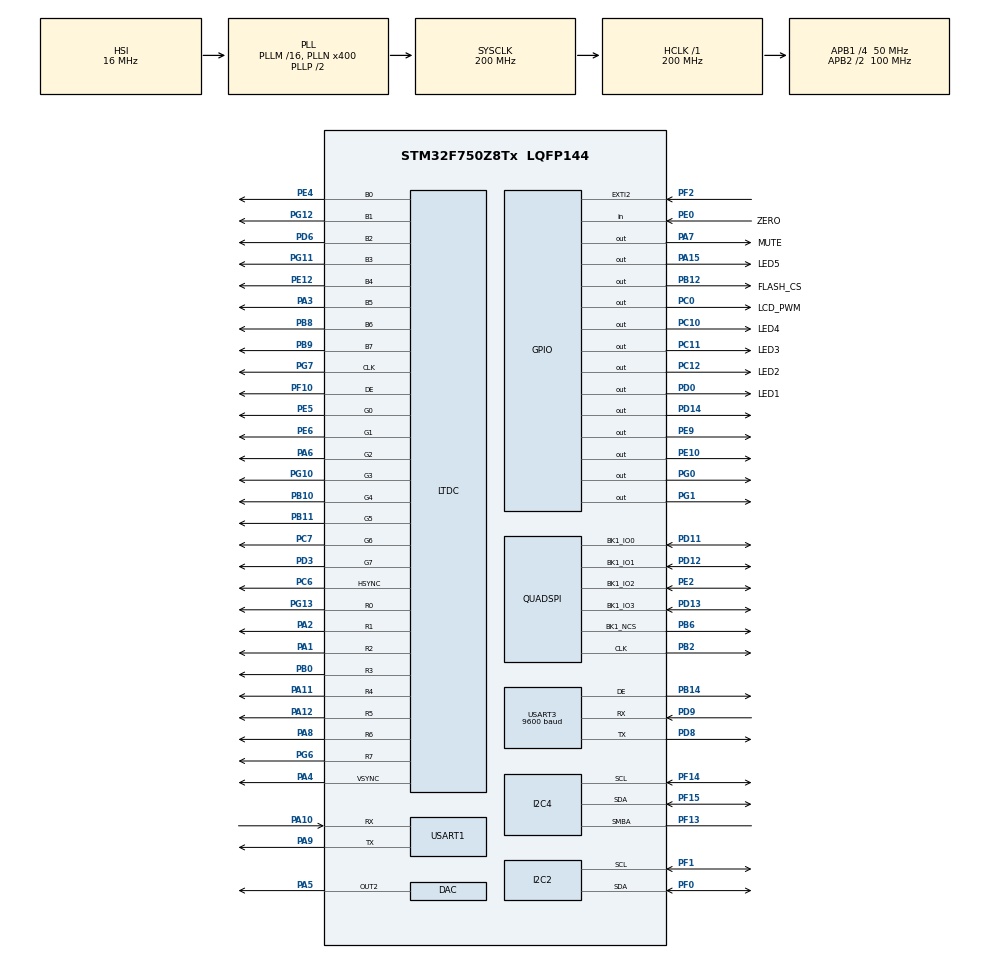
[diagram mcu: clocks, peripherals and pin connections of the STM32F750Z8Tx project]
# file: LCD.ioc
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CORTEX_M7.ART_ACCLERATOR_ENABLE=0
CORTEX_M7.CPU_DCache=Disabled
CORTEX_M7.CPU_ICache=Disabled
CORTEX_M7.PREFETCH_ENABLE=0
DAC.DAC_Trigger2=DAC_TRIGGER_NONE
DMA2D.ColorMode=DMA2D_OUTPUT_RGB565
Dma.I2C2_RX.1.Direction=DMA_PERIPH_TO_MEMORY
Dma.I2C2_RX.1.FIFOMode=DMA_FIFOMODE_DISABLE
Dma.I2C2_RX.1.Instance=DMA1_Stream2
Dma.I2C2_RX.1.MemDataAlignment=DMA_MDATAALIGN_BYTE
Dma.I2C2_RX.1.MemInc=DMA_MINC_ENABLE
Dma.I2C2_RX.1.Mode=DMA_CIRCULAR
Dma.I2C2_RX.1.PeriphDataAlignment=DMA_PDATAALIGN_BYTE
Dma.I2C2_RX.1.PeriphInc=DMA_PINC_DISABLE
Dma.I2C2_RX.1.Priority=DMA_PRIORITY_LOW
Dma.QUADSPI.2.Direction=DMA_PERIPH_TO_MEMORY
Dma.QUADSPI.2.FIFOMode=DMA_FIFOMODE_DISABLE
Dma.QUADSPI.2.Instance=DMA2_Stream7
Dma.QUADSPI.2.MemDataAlignment=DMA_MDATAALIGN_BYTE
Dma.QUADSPI.2.MemInc=DMA_MINC_ENABLE
Dma.QUADSPI.2.Mode=DMA_NORMAL
Dma.QUADSPI.2.PeriphDataAlignment=DMA_PDATAALIGN_BYTE
Dma.QUADSPI.2.PeriphInc=DMA_PINC_DISABLE
Dma.QUADSPI.2.Priority=DMA_PRIORITY_LOW
Dma.Request0=USART1_RX
Dma.Request1=I2C2_RX
Dma.Request2=QUADSPI
Dma.USART1_RX.0.Direction=DMA_PERIPH_TO_MEMORY
Dma.USART1_RX.0.FIFOMode=DMA_FIFOMODE_DISABLE
Dma.USART1_RX.0.Instance=DMA2_Stream2
Dma.USART1_RX.0.MemDataAlignment=DMA_MDATAALIGN_BYTE
Dma.USART1_RX.0.MemInc=DMA_MINC_ENABLE
Dma.USART1_RX.0.Mode=DMA_CIRCULAR
Dma.USART1_RX.0.PeriphDataAlignment=DMA_PDATAALIGN_BYTE
Dma.USART1_RX.0.PeriphInc=DMA_PINC_DISABLE
Dma.USART1_RX.0.Priority=DMA_PRIORITY_LOW
I2C2.Speed=10
I2C2.Timing=0xC00083FB
I2C4.Timeout=0x00008262
I2C4.Timing=0x00C0EAFF
IWDG.Prescaler=IWDG_PRESCALER_16
LTDC.ActiveH=272
LTDC.ActiveW=480
LTDC.Alpha_L0=255
LTDC.Alpha_L1=255
LTDC.BlendingFactor1_L0=LTDC_BLENDING_FACTOR1_CA
LTDC.BlendingFactor1_L1=LTDC_BLENDING_FACTOR1_PAxCA
LTDC.BlendingFactor2_L0=LTDC_BLENDING_FACTOR2_CA
LTDC.BlendingFactor2_L1=LTDC_BLENDING_FACTOR2_PAxCA
LTDC.Blue=255
LTDC.Blue_L0=0
LTDC.Blue_L1=255
LTDC.Green=255
LTDC.Green_L0=0
LTDC.Green_L1=255
LTDC.HBP=43
LTDC.HFP=8
LTDC.HSync=4
LTDC.ImageHeight_L0=272
LTDC.ImageWidth_L0=480
LTDC.Layers=0
LTDC.PixelFormat_L0=LTDC_PIXEL_FORMAT_RGB565
LTDC.PixelFormat_L1=LTDC_PIXEL_FORMAT_RGB565
LTDC.Red=255
LTDC.Red_L0=0
LTDC.VBP=12
LTDC.VFP=8
LTDC.VSync=4
LTDC.WindowX0_L1=160
LTDC.WindowX1_L0=480
LTDC.WindowX1_L1=480
LTDC.WindowY0_L1=32
LTDC.WindowY1_L0=272
LTDC.WindowY1_L1=272
Mcu.Family=STM32F7
Mcu.Name=STM32F750Z8Tx
Mcu.Package=LQFP144
Mcu.UserConstants=RK043FN48H_HSYNC,41;RK043FN48H_HBP,13;RK043FN48H_HFP,32;RK043FN48H_VSYNC,10;RK043FN48H_VBP,2;RK043FN48H_VFP,2
NVIC.DMA1_Stream2_IRQn=true\:0\:0\:false\:false\:true\:false\:true
NVIC.DMA2_Stream2_IRQn=true\:0\:0\:false\:false\:true\:false\:true
NVIC.DMA2_Stream7_IRQn=true\:0\:0\:false\:false\:true\:false\:true
NVIC.PVD_IRQn=true\:0\:0\:false\:false\:true\:true\:true
NVIC.PriorityGroup=NVIC_PRIORITYGROUP_4
NVIC.QUADSPI_IRQn=true\:0\:0\:false\:false\:true\:true\:true
NVIC.TIM1_UP_TIM10_IRQn=true\:0\:0\:false\:false\:true\:false\:true
NVIC.TIM6_DAC_IRQn=true\:0\:0\:false\:false\:true\:true\:true
NVIC.TIM7_IRQn=true\:0\:0\:false\:false\:true\:true\:true
NVIC.TimeBase=TIM1_UP_TIM10_IRQn
NVIC.TimeBaseIP=TIM1
NVIC.USART3_IRQn=true\:0\:0\:false\:false\:true\:true\:true
PA1.Mode=RGB888
PA1.Signal=LTDC_R2
PA10.Mode=Asynchronous
PA10.Signal=USART1_RX
PA11.Mode=RGB888
PA11.Signal=LTDC_R4
PA12.Mode=RGB888
PA12.Signal=LTDC_R5
PA13.Mode=Serial_Wire
PA13.Signal=SYS_JTMS-SWDIO
PA14.Mode=Serial_Wire
PA14.Signal=SYS_JTCK-SWCLK
PA15.GPIO_Label=LED5
PA15.GPIO_ModeDefaultOutputPP=GPIO_MODE_OUTPUT_PP
PA15.GPIO_PuPd=GPIO_NOPULL
PA15.GPIO_Speed=GPIO_SPEED_FREQ_LOW
PA15.PinState=GPIO_PIN_RESET
PA15.Signal=GPIO_Output
PA2.Mode=RGB888
PA2.Signal=LTDC_R1
PA3.Mode=RGB888
PA3.Signal=LTDC_B5
PA4.Mode=RGB888
PA4.Signal=LTDC_VSYNC
PA5.Signal=COMP_DAC2_group
PA6.Mode=RGB888
PA6.Signal=LTDC_G2
PA7.GPIO_Label=MUTE
PA7.GPIO_ModeDefaultOutputPP=GPIO_MODE_OUTPUT_PP
PA7.GPIO_PuPd=GPIO_NOPULL
PA7.GPIO_Speed=GPIO_SPEED_FREQ_LOW
PA7.PinState=GPIO_PIN_RESET
PA7.Signal=GPIO_Output
PA8.Mode=RGB888
PA8.Signal=LTDC_R6
PA9.Mode=Asynchronous
PA9.Signal=USART1_TX
PB0.Mode=RGB888
PB0.Signal=LTDC_R3
PB10.Mode=RGB888
PB10.Signal=LTDC_G4
PB11.Mode=RGB888
PB11.Signal=LTDC_G5
PB12.GPIO_Label=FLASH_CS
PB12.Signal=GPIO_Output
PB14.Mode=Hardware Flow Control (RS485)
PB14.Signal=USART3_DE
PB2.Mode=Single Bank 1
PB2.Signal=QUADSPI_CLK
PB6.Mode=Single Bank 1
PB6.Signal=QUADSPI_BK1_NCS
PB8.Mode=RGB888
PB8.Signal=LTDC_B6
PB9.Mode=RGB888
PB9.Signal=LTDC_B7
PC0.GPIO_Label=LCD_PWM
PC0.GPIO_ModeDefaultOutputPP=GPIO_MODE_OUTPUT_PP
PC0.GPIO_PuPd=GPIO_NOPULL
PC0.GPIO_Speed=GPIO_SPEED_FREQ_LOW
PC0.PinState=GPIO_PIN_RESET
PC0.Signal=GPIO_Output
PC10.GPIO_Label=LED4
PC10.GPIO_ModeDefaultOutputPP=GPIO_MODE_OUTPUT_PP
PC10.GPIO_PuPd=GPIO_NOPULL
PC10.GPIO_Speed=GPIO_SPEED_FREQ_LOW
PC10.PinState=GPIO_PIN_RESET
PC10.Signal=GPIO_Output
PC11.GPIO_Label=LED3
PC11.GPIO_ModeDefaultOutputPP=GPIO_MODE_OUTPUT_PP
PC11.GPIO_PuPd=GPIO_NOPULL
PC11.GPIO_Speed=GPIO_SPEED_FREQ_LOW
PC11.PinState=GPIO_PIN_RESET
PC11.Signal=GPIO_Output
PC12.GPIO_Label=LED2
PC12.GPIO_ModeDefaultOutputPP=GPIO_MODE_OUTPUT_PP
PC12.GPIO_PuPd=GPIO_NOPULL
PC12.GPIO_Speed=GPIO_SPEED_FREQ_LOW
PC12.PinState=GPIO_PIN_RESET
PC12.Signal=GPIO_Output
PC14/OSC32_IN.Mode=LSE-External-Oscillator
PC14/OSC32_IN.Signal=RCC_OSC32_IN
PC15/OSC32_OUT.Mode=LSE-External-Oscillator
PC15/OSC32_OUT.Signal=RCC_OSC32_OUT
PC6.Mode=RGB888
PC6.Signal=LTDC_HSYNC
PC7.Mode=RGB888
PC7.Signal=LTDC_G6
PD0.GPIO_Label=LED1
PD0.GPIO_ModeDefaultOutputPP=GPIO_MODE_OUTPUT_PP
PD0.GPIO_PuPd=GPIO_NOPULL
PD0.GPIO_Speed=GPIO_SPEED_FREQ_LOW
PD0.PinState=GPIO_PIN_RESET
PD0.Signal=GPIO_Output
PD11.Mode=Single Bank 1
PD11.Signal=QUADSPI_BK1_IO0
PD12.Mode=Single Bank 1
PD12.Signal=QUADSPI_BK1_IO1
PD13.Mode=Single Bank 1
PD13.Signal=QUADSPI_BK1_IO3
PD14.Signal=GPIO_Output
PD3.Mode=RGB888
PD3.Signal=LTDC_G7
PD6.Mode=RGB888
PD6.Signal=LTDC_B2
PD8.Mode=Asynchronous
PD8.Signal=USART3_TX
PD9.Mode=Asynchronous
PD9.Signal=USART3_RX
PE0.GPIO_Label=ZERO
PE0.Signal=GPIO_Input
PE10.Signal=GPIO_Output
PE12.Mode=RGB888
PE12.Signal=LTDC_B4
PE2.Mode=Single Bank 1
PE2.Signal=QUADSPI_BK1_IO2
PE4.Mode=RGB888
PE4.Signal=LTDC_B0
PE5.Mode=RGB888
PE5.Signal=LTDC_G0
PE6.Mode=RGB888
PE6.Signal=LTDC_G1
PE9.Signal=GPIO_Output
PF0.Mode=I2C
PF0.Signal=I2C2_SDA
PF1.Mode=I2C
PF1.Signal=I2C2_SCL
PF10.Mode=RGB888
PF10.Signal=LTDC_DE
PF13.Mode=SMBus-Alert-mode
PF13.Signal=I2C4_SMBA
PF14.Mode=SMBus-Alert-mode
PF14.Signal=I2C4_SCL
PF15.Mode=SMBus-Alert-mode
PF15.Signal=I2C4_SDA
PF2.GPIO_ModeDefaultEXTI=GPIO_MODE_IT_RISING
PF2.GPIO_PuPd=GPIO_NOPULL
PF2.Signal=GPXTI2
PG0.Signal=GPIO_Output
PG1.Signal=GPIO_Output
PG10.Mode=RGB888
PG10.Signal=LTDC_G3
PG11.Mode=RGB888
PG11.Signal=LTDC_B3
PG12.Mode=RGB888
PG12.Signal=LTDC_B1
PG13.Mode=RGB888
PG13.Signal=LTDC_R0
PG6.Mode=RGB888
PG6.Signal=LTDC_R7
PG7.Mode=RGB888
PG7.Signal=LTDC_CLK
PH0/OSC_IN.Mode=HSE-External-Oscillator
PH0/OSC_IN.Signal=RCC_OSC_IN
PH1/OSC_OUT.Mode=HSE-External-Oscillator
PH1/OSC_OUT.Signal=RCC_OSC_OUT
ProjectManager.HeapSize=0x200
ProjectManager.StackSize=0x400
ProjectManager.TargetToolchain=MDK-ARM V5
QUADSPI.ChipSelectHighTime=QSPI_CS_HIGH_TIME_3_CYCLE
QUADSPI.ClockPrescaler=10
QUADSPI.FifoThreshold=4
QUADSPI.FlashSize=24
QUADSPI.SampleShifting=QSPI_SAMPLE_SHIFTING_NONE
RCC.AHBFreq_Value=200000000
RCC.APB1CLKDivider=RCC_HCLK_DIV4
RCC.APB1Freq_Value=50000000
RCC.APB1TimFreq_Value=100000000
RCC.APB2CLKDivider=RCC_HCLK_DIV2
RCC.APB2Freq_Value=100000000
RCC.APB2TimFreq_Value=200000000
RCC.CortexFreq_Value=200000000
RCC.HCLKFreq_Value=200000000
RCC.HSE_VALUE=8000000
RCC.HSI_VALUE=16000000
RCC.PLLN=400
RCC.PLLSAIR=5
RCC.PLLSAIRDiv=RCC_PLLSAIDIVR_4
RCC.RTCClockSelection=RCC_RTCCLKSOURCE_LSE
RCC.SYSCLKFreq_VALUE=200000000
RCC.SYSCLKSource=RCC_SYSCLKSOURCE_PLLCLK
RCC.USBFreq_Value=200000000
RCC.VCOOutputFreq_Value=400000000
RTC.Alarm-Alarm\ A=RTC_ALARM_A
RTC.AsynchPrediv=128-1
RTC.SynchPrediv=256-1
SH.COMP_DAC2_group.0=DAC_OUT2,DAC_OUT2
STMicroelectronics.X-CUBE-TOUCHGFX.4.13.0.ApplicationCcGraphicsJjApplication=TouchGFXOoGenerator
STMicroelectronics.X-CUBE-TOUCHGFX.4.13.0.tgfx_display_interface=disp_ltdc
STMicroelectronics.X-CUBE-TOUCHGFX.4.13.0.tgfx_hardware_accelerator=dma_none
STMicroelectronics.X-CUBE-TOUCHGFX.4.13.0.tgfx_ltdc_height=480
STMicroelectronics.X-CUBE-TOUCHGFX.4.13.0.tgfx_ltdc_width=640
STMicroelectronics.X-CUBE-TOUCHGFX.4.13.0.tgfx_pixel_format=RGB888\:24
STMicroelectronics.X-CUBE-TOUCHGFX.4.13.0.tgfx_vsync=vsync_ltdc
TIM10.AutoReloadPreload=TIM_AUTORELOAD_PRELOAD_DISABLE
TIM10.ClockDivision=TIM_CLOCKDIVISION_DIV2
TIM10.Period=2000-1
TIM10.Prescaler=100-1
TIM6.AutoReloadPreload=TIM_AUTORELOAD_PRELOAD_DISABLE
TIM6.Period=500-1
TIM6.Prescaler=25-1
TIM7.Period=10000-1
TIM7.Prescaler=100-1
TIM7.TIM_MasterOutputTrigger=TIM_TRGO_RESET
USART1.VirtualMode-Asynchronous=VM_ASYNC
USART3.BaudRate=9600
USART3.UART_DEPolarity=UART_DE_POLARITY_LOW
USART3.VirtualMode-Asynchronous=VM_ASYNC
USART3.VirtualMode-Hardware\ Flow\ Control\ (RS485)=VM_ASYNC
VP_DMA2D_VS_DMA2D.Mode=DMA2D_Activate
VP_IWDG_VS_IWDG.Mode=IWDG_Activate
VP_RTC_VS_RTC_Activate.Mode=RTC_Enabled
VP_RTC_VS_RTC_Alarm_A_Intern.Mode=Alarm A
VP_RTC_VS_RTC_Calendar.Mode=RTC_Calendar
VP_SYS_VS_tim1.Mode=TIM1
VP_TIM10_VS_ClockSourceINT.Mode=Enable_Timer
VP_TIM6_VS_ClockSourceINT.Mode=Enable_Timer
VP_TIM7_VS_ClockSourceINT.Mode=Enable_Timer
board=custom

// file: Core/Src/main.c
/* USER CODE BEGIN Header */
/**
  ******************************************************************************
  * @file           : main.c
  * @brief          : Main program body
  ******************************************************************************
  * @attention
  *
  * <h2><center>&copy; Copyright (c) 2020 STMicroelectronics.
  * All rights reserved.</center></h2>
  *
  * This software component is licensed by ST under Ultimate Liberty license
  * SLA0044, the "License"; You may not use this file except in compliance with
  * the License. You may obtain a copy of the License at:
  *                             www.st.com/SLA0044
  *
  ******************************************************************************
  */
/* USER CODE END Header */

#include "main.h"
#include "dac.h"
#include "dma.h"
#include "dma2d.h"
#include "i2c.h"
#include "iwdg.h"
#include "ltdc.h"
#include "quadspi.h"
#include "rtc.h"
#include "tim.h"
#include "usart.h"
#include "gpio.h"

/* USER CODE BEGIN Includes */
#include "user.h"
#include "led.h"
#include "qspi.h"
/* USER CODE END Includes */

void SystemClock_Config(void);

int main(void)
{

  /* MCU Configuration--------------------------------------------------------*/

  /* Reset of all peripherals, Initializes the Flash interface and the Systick. */
  HAL_Init();

  /* Configure the system clock */
  SystemClock_Config();

  /* Initialize all configured peripherals */
  MX_GPIO_Init();
  MX_DMA_Init();
  MX_DAC_Init();
  MX_I2C2_Init();
  MX_I2C4_SMBUS_Init();
  MX_LTDC_Init();
  MX_USART1_UART_Init();
  MX_USART3_UART_Init();
  MX_TIM6_Init();
  MX_TIM7_Init();
  MX_DMA2D_Init();
  MX_QUADSPI_Init();
  MX_RTC_Init();
  MX_IWDG_Init();
  MX_TIM10_Init();
  /* USER CODE BEGIN 2 */

  userStart();
  muteSound (_ON);
  MX_USART1_UART_Init();
  MX_USART3_UART_Init();
  messageInit();

  /* USER CODE END 2 */

  /* Infinite loop */
  /* USER CODE BEGIN WHILE */
  while (1)
  {
	  userWhile();

    /* USER CODE END WHILE */

  }
}

void SystemClock_Config(void)
{
  RCC_OscInitTypeDef RCC_OscInitStruct = {0};
  RCC_ClkInitTypeDef RCC_ClkInitStruct = {0};
  RCC_PeriphCLKInitTypeDef PeriphClkInitStruct = {0};

  /** Configure LSE Drive Capability
  */
  HAL_PWR_EnableBkUpAccess();
  __HAL_RCC_LSEDRIVE_CONFIG(RCC_LSEDRIVE_LOW);
  /** Configure the main internal regulator output voltage
  */
  __HAL_RCC_PWR_CLK_ENABLE();
  __HAL_PWR_VOLTAGESCALING_CONFIG(PWR_REGULATOR_VOLTAGE_SCALE1);
  /** Initializes the CPU, AHB and APB busses clocks
  */
  RCC_OscInitStruct.OscillatorType = RCC_OSCILLATORTYPE_HSI|RCC_OSCILLATORTYPE_LSI
                              |RCC_OSCILLATORTYPE_LSE;
  RCC_OscInitStruct.LSEState = RCC_LSE_ON;
  RCC_OscInitStruct.HSIState = RCC_HSI_ON;
  RCC_OscInitStruct.HSICalibrationValue = RCC_HSICALIBRATION_DEFAULT;
  RCC_OscInitStruct.LSIState = RCC_LSI_ON;
  RCC_OscInitStruct.PLL.PLLState = RCC_PLL_ON;
  RCC_OscInitStruct.PLL.PLLSource = RCC_PLLSOURCE_HSI;
  RCC_OscInitStruct.PLL.PLLM = 16;
  RCC_OscInitStruct.PLL.PLLN = 400;
  RCC_OscInitStruct.PLL.PLLP = RCC_PLLP_DIV2;
  RCC_OscInitStruct.PLL.PLLQ = 2;
  if (HAL_RCC_OscConfig(&RCC_OscInitStruct) != HAL_OK)
  {
    Error_Handler();
  }
  /** Activate the Over-Drive mode
  */
  if (HAL_PWREx_EnableOverDrive() != HAL_OK)
  {
    Error_Handler();
  }
  /** Initializes the CPU, AHB and APB busses clocks
  */
  RCC_ClkInitStruct.ClockType = RCC_CLOCKTYPE_HCLK|RCC_CLOCKTYPE_SYSCLK
                              |RCC_CLOCKTYPE_PCLK1|RCC_CLOCKTYPE_PCLK2;
  RCC_ClkInitStruct.SYSCLKSource = RCC_SYSCLKSOURCE_PLLCLK;
  RCC_ClkInitStruct.AHBCLKDivider = RCC_SYSCLK_DIV1;
  RCC_ClkInitStruct.APB1CLKDivider = RCC_HCLK_DIV4;
  RCC_ClkInitStruct.APB2CLKDivider = RCC_HCLK_DIV2;

  if (HAL_RCC_ClockConfig(&RCC_ClkInitStruct, FLASH_LATENCY_6) != HAL_OK)
  {
    Error_Handler();
  }
  PeriphClkInitStruct.PeriphClockSelection = RCC_PERIPHCLK_LTDC|RCC_PERIPHCLK_RTC
                              |RCC_PERIPHCLK_USART1|RCC_PERIPHCLK_USART3
                              |RCC_PERIPHCLK_I2C2|RCC_PERIPHCLK_I2C4;
  PeriphClkInitStruct.PLLSAI.PLLSAIN = 192;
  PeriphClkInitStruct.PLLSAI.PLLSAIR = 5;
  PeriphClkInitStruct.PLLSAI.PLLSAIQ = 2;
  PeriphClkInitStruct.PLLSAI.PLLSAIP = RCC_PLLSAIP_DIV2;
  PeriphClkInitStruct.PLLSAIDivQ = 1;
  PeriphClkInitStruct.PLLSAIDivR = RCC_PLLSAIDIVR_4;
  PeriphClkInitStruct.RTCClockSelection = RCC_RTCCLKSOURCE_LSE;
  PeriphClkInitStruct.Usart1ClockSelection = RCC_USART1CLKSOURCE_PCLK2;
  PeriphClkInitStruct.Usart3ClockSelection = RCC_USART3CLKSOURCE_PCLK1;
  PeriphClkInitStruct.I2c2ClockSelection = RCC_I2C2CLKSOURCE_PCLK1;
  PeriphClkInitStruct.I2c4ClockSelection = RCC_I2C4CLKSOURCE_PCLK1;
  if (HAL_RCCEx_PeriphCLKConfig(&PeriphClkInitStruct) != HAL_OK)
  {
    Error_Handler();
  }
}

 /**
  * @brief  Period elapsed callback in non blocking mode
  * @note   This function is called  when TIM1 interrupt took place, inside
  * HAL_TIM_IRQHandler(). It makes a direct call to HAL_IncTick() to increment
  * a global variable "uwTick" used as application time base.
  * @param  htim : TIM handle
  * @retval None
  */
void HAL_TIM_PeriodElapsedCallback(TIM_HandleTypeDef *htim)
{
  if (htim->Instance == TIM1) {
    HAL_IncTick();
  }
  /* USER CODE BEGIN Callback 1 */
	else
	{
		user_TIM_PeriodElapsedCallback(htim);
	}
  /* USER CODE END Callback 1 */
}

void Error_Handler(void)
{
  /* USER CODE BEGIN Error_Handler_Debug */
  /* User can add his own implementation to report the HAL error return state */
	LED_Off(LED4);
  /* USER CODE END Error_Handler_Debug */
}

/************************ (C) COPYRIGHT STMicroelectronics *****END OF FILE****/
